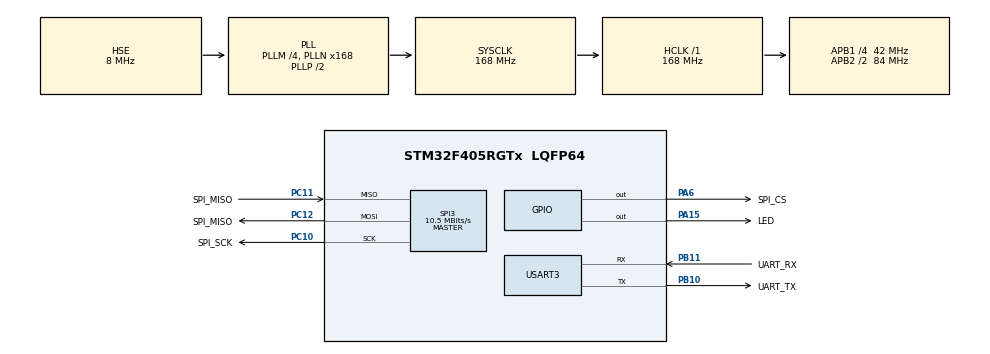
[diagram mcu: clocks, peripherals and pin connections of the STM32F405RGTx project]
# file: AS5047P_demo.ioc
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Dma.Request0=SPI3_RX
Dma.Request1=SPI3_TX
Dma.Request2=USART3_TX
Dma.SPI3_RX.0.Direction=DMA_PERIPH_TO_MEMORY
Dma.SPI3_RX.0.FIFOMode=DMA_FIFOMODE_DISABLE
Dma.SPI3_RX.0.Instance=DMA1_Stream0
Dma.SPI3_RX.0.MemDataAlignment=DMA_MDATAALIGN_HALFWORD
Dma.SPI3_RX.0.MemInc=DMA_MINC_ENABLE
Dma.SPI3_RX.0.Mode=DMA_NORMAL
Dma.SPI3_RX.0.PeriphDataAlignment=DMA_PDATAALIGN_HALFWORD
Dma.SPI3_RX.0.PeriphInc=DMA_PINC_DISABLE
Dma.SPI3_RX.0.Priority=DMA_PRIORITY_LOW
Dma.SPI3_TX.1.Direction=DMA_MEMORY_TO_PERIPH
Dma.SPI3_TX.1.FIFOMode=DMA_FIFOMODE_DISABLE
Dma.SPI3_TX.1.Instance=DMA1_Stream5
Dma.SPI3_TX.1.MemDataAlignment=DMA_MDATAALIGN_HALFWORD
Dma.SPI3_TX.1.MemInc=DMA_MINC_ENABLE
Dma.SPI3_TX.1.Mode=DMA_NORMAL
Dma.SPI3_TX.1.PeriphDataAlignment=DMA_PDATAALIGN_HALFWORD
Dma.SPI3_TX.1.PeriphInc=DMA_PINC_DISABLE
Dma.SPI3_TX.1.Priority=DMA_PRIORITY_LOW
Dma.USART3_TX.2.Direction=DMA_MEMORY_TO_PERIPH
Dma.USART3_TX.2.FIFOMode=DMA_FIFOMODE_DISABLE
Dma.USART3_TX.2.Instance=DMA1_Stream3
Dma.USART3_TX.2.MemDataAlignment=DMA_MDATAALIGN_BYTE
Dma.USART3_TX.2.MemInc=DMA_MINC_ENABLE
Dma.USART3_TX.2.Mode=DMA_NORMAL
Dma.USART3_TX.2.PeriphDataAlignment=DMA_PDATAALIGN_BYTE
Dma.USART3_TX.2.PeriphInc=DMA_PINC_DISABLE
Dma.USART3_TX.2.Priority=DMA_PRIORITY_LOW
FREERTOS.Tasks01=defaultTask,0,128,StartDefaultTask,Default,NULL
Mcu.Family=STM32F4
Mcu.Name=STM32F405RGTx
Mcu.Package=LQFP64
NVIC.DMA1_Stream0_IRQn=true\:5\:0\:false\:false\:true\:true\:false\:true
NVIC.DMA1_Stream3_IRQn=true\:5\:0\:false\:false\:true\:true\:false\:true
NVIC.DMA1_Stream5_IRQn=true\:5\:0\:false\:false\:true\:true\:false\:true
NVIC.PriorityGroup=NVIC_PRIORITYGROUP_4
NVIC.TIM6_DAC_IRQn=true\:0\:0\:false\:false\:true\:false\:false\:true
NVIC.TimeBase=TIM6_DAC_IRQn
NVIC.TimeBaseIP=TIM6
NVIC.USART3_IRQn=true\:5\:0\:false\:false\:true\:true\:true\:true
PA15.GPIO_Label=LED
PA15.Signal=GPIO_Output
PA6.GPIO_Label=SPI_CS
PA6.Signal=GPIO_Output
PB10.GPIO_Label=UART_TX
PB10.Mode=Asynchronous
PB10.Signal=USART3_TX
PB11.GPIO_Label=UART_RX
PB11.Mode=Asynchronous
PB11.Signal=USART3_RX
PC10.GPIO_Label=SPI_SCK
PC10.Mode=Full_Duplex_Master
PC10.Signal=SPI3_SCK
PC11.GPIO_Label=SPI_MISO
PC11.Mode=Full_Duplex_Master
PC11.Signal=SPI3_MISO
PC12.GPIO_Label=SPI_MISO
PC12.Mode=Full_Duplex_Master
PC12.Signal=SPI3_MOSI
PH0-OSC_IN.Mode=HSE-External-Oscillator
PH0-OSC_IN.Signal=RCC_OSC_IN
PH1-OSC_OUT.Mode=HSE-External-Oscillator
PH1-OSC_OUT.Signal=RCC_OSC_OUT
ProjectManager.HeapSize=0x200
ProjectManager.StackSize=0x400
ProjectManager.TargetToolchain=Makefile
RCC.48MHZClocksFreq_Value=84000000
RCC.AHBFreq_Value=168000000
RCC.APB1CLKDivider=RCC_HCLK_DIV4
RCC.APB1Freq_Value=42000000
RCC.APB1TimFreq_Value=84000000
RCC.APB2CLKDivider=RCC_HCLK_DIV2
RCC.APB2Freq_Value=84000000
RCC.APB2TimFreq_Value=168000000
RCC.CortexFreq_Value=168000000
RCC.HCLKFreq_Value=168000000
RCC.HSE_VALUE=8000000
RCC.HSI_VALUE=16000000
RCC.LSE_VALUE=32768
RCC.PLLM=4
RCC.PLLN=168
RCC.PLLSourceVirtual=RCC_PLLSOURCE_HSE
RCC.SYSCLKFreq_VALUE=168000000
RCC.SYSCLKSource=RCC_SYSCLKSOURCE_PLLCLK
RCC.VCOOutputFreq_Value=336000000
SPI3.BaudRatePrescaler=SPI_BAUDRATEPRESCALER_4
SPI3.CLKPhase=SPI_PHASE_2EDGE
SPI3.CalculateBaudRate=10.5 MBits/s
SPI3.DataSize=SPI_DATASIZE_16BIT
SPI3.Direction=SPI_DIRECTION_2LINES
SPI3.Mode=SPI_MODE_MASTER
SPI3.VirtualType=VM_MASTER
USART3.VirtualMode=VM_ASYNC
VP_FREERTOS_VS_CMSIS_V1.Mode=CMSIS_V1
VP_SYS_VS_tim6.Mode=TIM6
board=custom

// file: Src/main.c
/* USER CODE BEGIN Header */
/**
  ******************************************************************************
  * @file           : main.c
  * @brief          : Main program body
  ******************************************************************************
  * @attention
  *
  * <h2><center>&copy; Copyright (c) 2021 STMicroelectronics.
  * All rights reserved.</center></h2>
  *
  * This software component is licensed by ST under BSD 3-Clause license,
  * the "License"; You may not use this file except in compliance with the
  * License. You may obtain a copy of the License at:
  *                        opensource.org/licenses/BSD-3-Clause
  *
  ******************************************************************************
  */
/* USER CODE END Header */

#include "main.h"
#include "cmsis_os.h"
#include "dma.h"
#include "spi.h"
#include "usart.h"
#include "gpio.h"

void SystemClock_Config(void);
void MX_FREERTOS_Init(void);

int main(void)
{

  /* MCU Configuration--------------------------------------------------------*/

  /* Reset of all peripherals, Initializes the Flash interface and the Systick. */
  HAL_Init();

  /* Configure the system clock */
  SystemClock_Config();

  /* Initialize all configured peripherals */
  MX_GPIO_Init();
  MX_DMA_Init();
  MX_SPI3_Init();
  MX_USART3_UART_Init();

  /* Call init function for freertos objects (in freertos.c) */
  MX_FREERTOS_Init();

  /* Start scheduler */
  osKernelStart();

  /* We should never get here as control is now taken by the scheduler */

  /* Infinite loop */
  while (1)
  {

  }
}

void SystemClock_Config(void)
{
  RCC_OscInitTypeDef RCC_OscInitStruct = {0};
  RCC_ClkInitTypeDef RCC_ClkInitStruct = {0};

  /** Configure the main internal regulator output voltage
  */
  __HAL_RCC_PWR_CLK_ENABLE();
  __HAL_PWR_VOLTAGESCALING_CONFIG(PWR_REGULATOR_VOLTAGE_SCALE1);
  /** Initializes the CPU, AHB and APB busses clocks
  */
  RCC_OscInitStruct.OscillatorType = RCC_OSCILLATORTYPE_HSE;
  RCC_OscInitStruct.HSEState = RCC_HSE_ON;
  RCC_OscInitStruct.PLL.PLLState = RCC_PLL_ON;
  RCC_OscInitStruct.PLL.PLLSource = RCC_PLLSOURCE_HSE;
  RCC_OscInitStruct.PLL.PLLM = 4;
  RCC_OscInitStruct.PLL.PLLN = 168;
  RCC_OscInitStruct.PLL.PLLP = RCC_PLLP_DIV2;
  RCC_OscInitStruct.PLL.PLLQ = 4;
  if (HAL_RCC_OscConfig(&RCC_OscInitStruct) != HAL_OK)
  {
    Error_Handler();
  }
  /** Initializes the CPU, AHB and APB busses clocks
  */
  RCC_ClkInitStruct.ClockType = RCC_CLOCKTYPE_HCLK|RCC_CLOCKTYPE_SYSCLK
                              |RCC_CLOCKTYPE_PCLK1|RCC_CLOCKTYPE_PCLK2;
  RCC_ClkInitStruct.SYSCLKSource = RCC_SYSCLKSOURCE_PLLCLK;
  RCC_ClkInitStruct.AHBCLKDivider = RCC_SYSCLK_DIV1;
  RCC_ClkInitStruct.APB1CLKDivider = RCC_HCLK_DIV4;
  RCC_ClkInitStruct.APB2CLKDivider = RCC_HCLK_DIV2;

  if (HAL_RCC_ClockConfig(&RCC_ClkInitStruct, FLASH_LATENCY_5) != HAL_OK)
  {
    Error_Handler();
  }
}

void HAL_TIM_PeriodElapsedCallback(TIM_HandleTypeDef *htim)
{
  if (htim->Instance == TIM6) {
    HAL_IncTick();
  }
}

void Error_Handler(void)
{
}

/************************ (C) COPYRIGHT STMicroelectronics *****END OF FILE****/

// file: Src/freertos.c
/* USER CODE BEGIN Header */
/**
  ******************************************************************************
  * File Name          : freertos.c
  * Description        : Code for freertos applications
  ******************************************************************************
  * @attention
  *
  * <h2><center>&copy; Copyright (c) 2021 STMicroelectronics.
  * All rights reserved.</center></h2>
  *
  * This software component is licensed by ST under Ultimate Liberty license
  * SLA0044, the "License"; You may not use this file except in compliance with
  * the License. You may obtain a copy of the License at:
  *                             www.st.com/SLA0044
  *
  ******************************************************************************
  */
/* USER CODE END Header */

#include "FreeRTOS.h"
#include "task.h"
#include "main.h"
#include "cmsis_os.h"

/* USER CODE BEGIN Includes */
#include "Zeng_encoder_as5047p.h"
/* USER CODE END Includes */

/* USER CODE BEGIN PTD */
osSemaphoreId sem_uart_dma;
/* USER CODE END PTD */

osThreadId defaultTaskHandle;

void StartDefaultTask(void const * argument);

void MX_FREERTOS_Init(void); /* (MISRA C 2004 rule 8.1) */

/* GetIdleTaskMemory prototype (linked to static allocation support) */
void vApplicationGetIdleTaskMemory( StaticTask_t **ppxIdleTaskTCBBuffer, StackType_t **ppxIdleTaskStackBuffer, uint32_t *pulIdleTaskStackSize );

/* USER CODE BEGIN GET_IDLE_TASK_MEMORY */
static StaticTask_t xIdleTaskTCBBuffer;
static StackType_t xIdleStack[configMINIMAL_STACK_SIZE];

void vApplicationGetIdleTaskMemory( StaticTask_t **ppxIdleTaskTCBBuffer, StackType_t **ppxIdleTaskStackBuffer, uint32_t *pulIdleTaskStackSize )
{
  *ppxIdleTaskTCBBuffer = &xIdleTaskTCBBuffer;
  *ppxIdleTaskStackBuffer = &xIdleStack[0];
  *pulIdleTaskStackSize = configMINIMAL_STACK_SIZE;
  /* place for user code */
}
/* USER CODE END GET_IDLE_TASK_MEMORY */

void MX_FREERTOS_Init(void) {

  /* USER CODE BEGIN RTOS_SEMAPHORES */
  /* add semaphores, ... */
  osSemaphoreDef(sem_uart_dma);
  sem_uart_dma = osSemaphoreCreate(osSemaphore(sem_uart_dma), 1);
  /* USER CODE END RTOS_SEMAPHORES */

  /* Create the thread(s) */
  /* definition and creation of defaultTask */
  osThreadDef(defaultTask, StartDefaultTask, osPriorityNormal, 0, 128);
  defaultTaskHandle = osThreadCreate(osThread(defaultTask), NULL);

}

void StartDefaultTask(void const * argument)
{
  /* USER CODE BEGIN StartDefaultTask */
  Zeng_encoder_as5047p_Init();
  LED_OFF();
  /* Infinite loop */
  for(;;)
  {
    LED_ON();
    osDelay(500);
    LED_OFF();
    osDelay(500);
  }
  /* USER CODE END StartDefaultTask */
}

/************************ (C) COPYRIGHT STMicroelectronics *****END OF FILE****/
